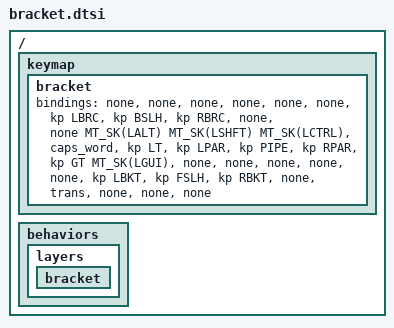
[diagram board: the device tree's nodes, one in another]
// Copyright (c) 2022 The ZMK Contributors
// SPDX-License-Identifier: MIT

#define B_BRACKET(key) B_LAYER(BRACKET, key)

/ {
    keymap {
        bracket {
            bindings = <
        // ╭──────────────┬──────────────┬──────────────┬──────────────┬──────────────╮   ╭──────────────┬──────────────┬──────────────┬──────────────┬──────────────╮
        // │              │              │              │              │              │   │              |  {           |  \           |  }           |              │
             &none          &none          &none          &none          &none              &none          &kp LBRC       &kp BSLH       &kp RBRC       &none
        // ├──────────────┼──────────────┼──────────────┼──────────────┼──────────────┤   ├──────────────┼──────────────┼──────────────┼──────────────┼──────────────┤
        // │              │  ALT         │  SHIFT       │  CONTROL     │              │   │  <           │  (           |  |           |  )           |  >           │
             &none          MT_SK(LALT)    MT_SK(LSHFT)   MT_SK(LCTRL)   &caps_word         &kp LT         &kp LPAR       &kp PIPE       &kp RPAR       &kp GT
        // ├──────────────┼──────────────┼──────────────┼──────────────┼──────────────┤   ├──────────────┼──────────────┼──────────────┼──────────────┼──────────────┤
        // │  GUI         │              │              │              │              │   │              |  [           |  /           |  ]           |              │
             MT_SK(LGUI)    &none          &none          &none          &none              &none          &kp LBKT       &kp FSLH       &kp RBKT       &none
        // ╰──────────────┴──────────────┴──────────────┼──────────────┼──────────────┤   ├──────────────┼──────────────┼──────────────┴──────────────┴──────────────╯
        //                                              |              |              |   |              |              |
                                                          &trans         &none              &none          &none
        //                                              ╰──────────────┴──────────────╯   ╰──────────────┴──────────────╯
            >;
        };
    };

    behaviors {
        layers {
            bracket {
            };
        };
    };
};
